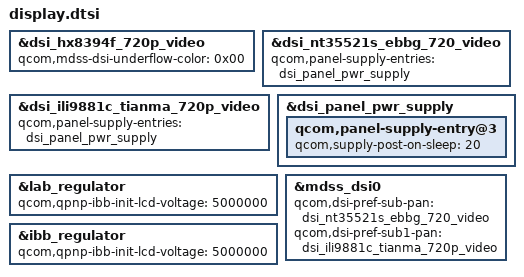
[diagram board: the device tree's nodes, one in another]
#include "panel/dsi-panel-nt35521s-ebbg-720p-video.dtsi"
#include "panel/dsi-panel-ili9881c-tianma-720p-video.dtsi"

&dsi_hx8394f_720p_video {
	qcom,mdss-dsi-underflow-color = <0x00>;
};

&dsi_nt35521s_ebbg_720_video {
	qcom,panel-supply-entries = <&dsi_panel_pwr_supply>;
};

&dsi_ili9881c_tianma_720p_video {
	qcom,panel-supply-entries = <&dsi_panel_pwr_supply>;
};

&dsi_panel_pwr_supply {
	qcom,panel-supply-entry@3 {
		qcom,supply-post-on-sleep = <20>;
	};
};

&lab_regulator {
	qcom,qpnp-ibb-init-lcd-voltage = <5000000>;
};

&ibb_regulator {
	qcom,qpnp-ibb-init-lcd-voltage = <5000000>;
};

&mdss_dsi0 {
	qcom,dsi-pref-sub-pan = <&dsi_nt35521s_ebbg_720_video>;
	qcom,dsi-pref-sub1-pan = <&dsi_ili9881c_tianma_720p_video>;
};
